# HC32F558 register map
File version: 1.0
CPU: CM4 r0p1, little endian, MPU, FPU, 4 interrupt priority bits
Registers are 32-bit, read-write, reset 0x0 unless marked. A register's access mark holds for its fields unless they carry their own. Offsets are from the block's base; [hi:lo] are bit positions; {n}, {i} and the like mark numbered series; 'fields as' and 'values as' point back to an identical list.

## HRPWM1 — desc HRPWM
Base 0x40034000
Same registers: HRPWM2 0x40034400, HRPWM3 0x40034800, HRPWM4 0x40034C00, HRPWM5 0x40035000, HRPWM6 0x40035400, HRPWM7 0x40035800, HRPWM8 0x40035C00
0x00 CNTER
  [16:0] CNT
0x04 UPDAR
  [16:0] UPDA
0x28 PHSCMP7A reset 0x3FFC0
  [17:0] PHSCMP7A
0x2C PHSCMP7B reset 0x3FFC0
  [17:0] PHSCMP7B
0x30 PHSCMP6A reset 0x3FFC0
  [17:0] PHSCMP6A
0x34 PHSCMP6B reset 0x3FFC0
  [17:0] PHSCMP6B
0x38 PHSCMP5A reset 0x3FFC0
  [17:0] PHSCMP5A
0x3C PHSCMP5B reset 0x3FFC0
  [17:0] PHSCMP5B
0x40 PHSCMP4A reset 0x3FFC0
  [17:0] PHSCMP4A
0x44 PHSCMP4B reset 0x3FFC0
  [17:0] PHSCMP4B
0x48 PHSCMP3A reset 0x3FFC0
  [17:0] PHSCMP3A
0x4C PHSCMP3B reset 0x3FFC0
  [17:0] PHSCMP3B
0x50 PHSCMP2A reset 0x3FFC0
  [17:0] PHSCMP2A
0x54 PHSCMP2B reset 0x3FFC0
  [17:0] PHSCMP2B
0x58 PHSCMP1A reset 0x3FFC0
  [17:0] PHSCMP1A
0x5C PHSCMP1B reset 0x3FFC0
  [17:0] PHSCMP1B
0x60 HRPERAR reset 0x1FFC0
  [16:0] HRPERA
0x64 HRPERBR reset 0x1FFC0
  [16:0] HRPERB
0x68 HRGCMAR reset 0x1FFC0
  [16:0] HRGCMA
0x6C HRGCMCR reset 0x1FFC0
  [16:0] HRGCMC
0x70 HRGCMBR reset 0x1FFC0
  [16:0] HRGCMB
0x74 HRGCMDR reset 0x1FFC0
  [16:0] HRGCMD
0x78 HRGCMER reset 0x1FFC0
  [16:0] HRGCME
0x7C HRGCMGR reset 0x1FFC0
  [16:0] HRGCMG
0x80 HRGCMFR reset 0x1FFC0
  [16:0] HRGCMF
0x84 HRGCMHR reset 0x1FFC0
  [16:0] HRGCMH
0x88 SCMAR reset 0x1FFC0
  [16:0] SCMA
0x8C SCMCR reset 0x1FFC0
  [16:0] SCMC
0x90 SCMBR reset 0x1FFC0
  [16:0] SCMB
0x94 SCMDR reset 0x1FFC0
  [16:0] SCMD
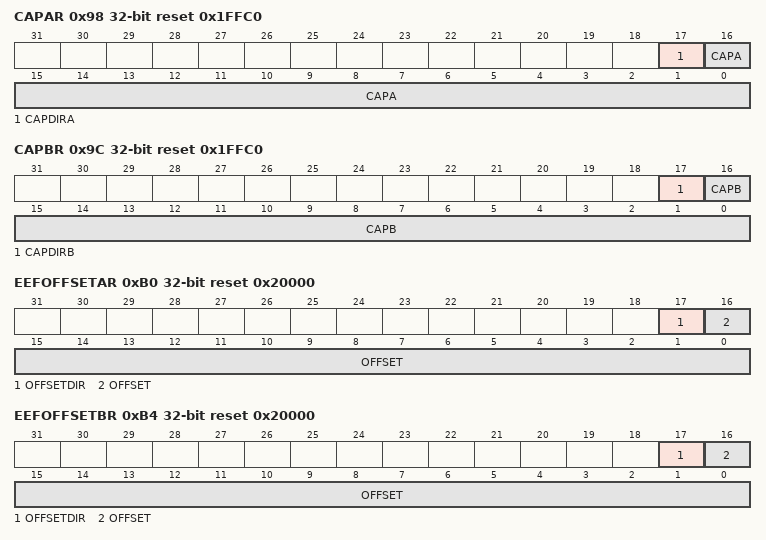
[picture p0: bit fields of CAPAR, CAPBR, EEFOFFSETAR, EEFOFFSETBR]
0x98 CAPAR reset 0x1FFC0
  [17] CAPDIRA ro, [16:0] CAPA
0x9C CAPBR reset 0x1FFC0
  [17] CAPDIRB ro, [16:0] CAPB
0xA0 HRDTUAR reset 0x1FFC0
  [16:0] HRDTUA
0xA4 HRDTUBR reset 0x1FFC0
  [16:0] HRDTUB
0xA8 HRDTDAR reset 0x1FFC0
  [16:0] HRDTDA
0xAC HRDTDBR reset 0x1FFC0
  [16:0] HRDTDB
0xB0 EEFOFFSETAR reset 0x20000
  [17] OFFSETDIR, [16:0] OFFSET
0xB4 EEFOFFSETBR reset 0x20000
  [17] OFFSETDIR, [16:0] OFFSET
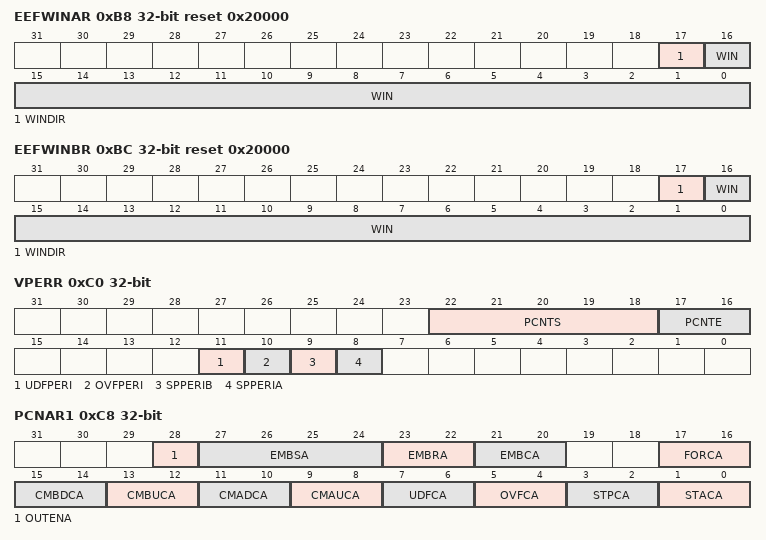
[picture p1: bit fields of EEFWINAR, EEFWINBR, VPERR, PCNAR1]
0xB8 EEFWINAR reset 0x20000
  [17] WINDIR, [16:0] WIN
0xBC EEFWINBR reset 0x20000
  [17] WINDIR, [16:0] WIN
0xC0 VPERR
  [22:18] PCNTS, [17:16] PCNTE, [11] UDFPERI, [10] OVFPERI, [9] SPPERIB, [8] SPPERIA
0xC4 BVPERR
  [22:18] PCNTS
0xC8 PCNAR1
  [28] OUTENA, [27:24] EMBSA, [23:22] EMBRA, [21:20] EMBCA, [17:16] FORCA, [15:14] CMBDCA, [13:12] CMBUCA, [11:10] CMADCA, [9:8] CMAUCA, [7:6] UDFCA, [5:4] OVFCA, [3:2] STPCA, [1:0] STACA
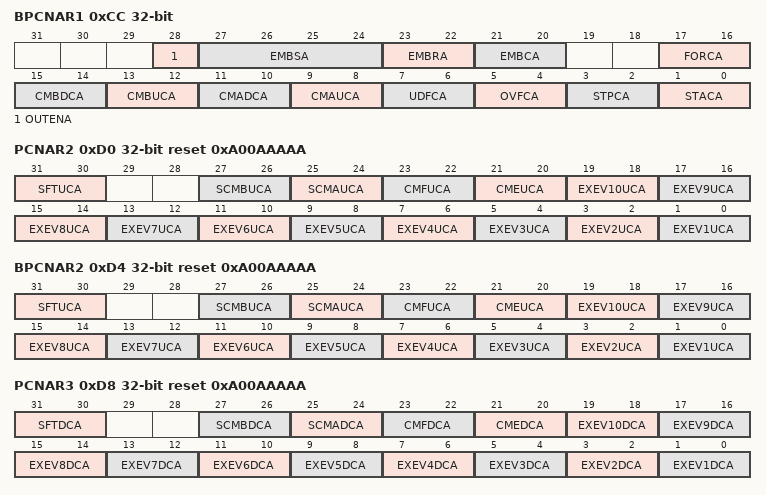
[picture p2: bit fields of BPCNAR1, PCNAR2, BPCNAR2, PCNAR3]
0xCC BPCNAR1
  fields as PCNAR1
0xD0 PCNAR2 reset 0xA00AAAAA
  [31:30] SFTUCA, [27:26] SCMBUCA, [25:24] SCMAUCA, [23:22] CMFUCA, [21:20] CMEUCA, [2n-1:2n-2] EXEV{n}UCA (n=1..10)
0xD4 BPCNAR2 reset 0xA00AAAAA
  fields as PCNAR2
0xD8 PCNAR3 reset 0xA00AAAAA
  [31:30] SFTDCA, [27:26] SCMBDCA, [25:24] SCMADCA, [23:22] CMFDCA, [21:20] CMEDCA, [2n-1:2n-2] EXEV{n}DCA (n=1..10)
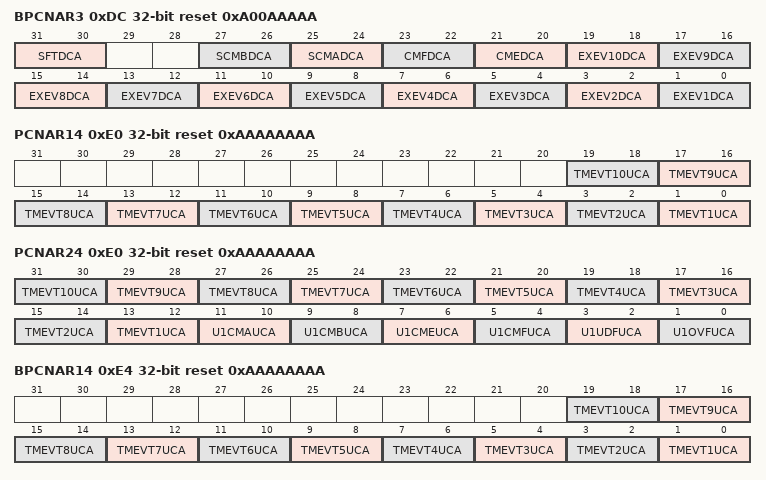
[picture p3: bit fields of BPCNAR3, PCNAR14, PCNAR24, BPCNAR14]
0xDC BPCNAR3 reset 0xA00AAAAA
  fields as PCNAR3
0xE0 PCNAR14 reset 0xAAAAAAAA
  [2n-1:2n-2] TMEVT{n}UCA (n=1..10)
0xE0 PCNAR24 reset 0xAAAAAAAA (alternate view of PCNAR14)
  [2n+11:2n+10] TMEVT{n}UCA (n=1..10), [11:10] U1CMAUCA, [9:8] U1CMBUCA, [7:6] U1CMEUCA, [5:4] U1CMFUCA, [3:2] U1UDFUCA, [1:0] U1OVFUCA
0xE4 BPCNAR14 reset 0xAAAAAAAA
  [2n-1:2n-2] TMEVT{n}UCA (n=1..10)
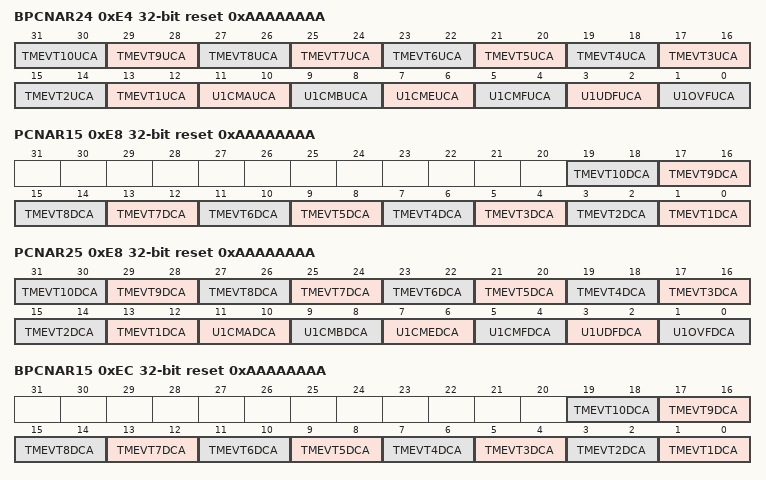
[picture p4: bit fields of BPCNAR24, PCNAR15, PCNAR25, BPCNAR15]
0xE4 BPCNAR24 reset 0xAAAAAAAA (alternate view of BPCNAR14)
  fields as PCNAR24
0xE8 PCNAR15 reset 0xAAAAAAAA
  [2n-1:2n-2] TMEVT{n}DCA (n=1..10)
0xE8 PCNAR25 reset 0xAAAAAAAA (alternate view of PCNAR15)
  [2n+11:2n+10] TMEVT{n}DCA (n=1..10), [11:10] U1CMADCA, [9:8] U1CMBDCA, [7:6] U1CMEDCA, [5:4] U1CMFDCA, [3:2] U1UDFDCA, [1:0] U1OVFDCA
0xEC BPCNAR15 reset 0xAAAAAAAA
  [2n-1:2n-2] TMEVT{n}DCA (n=1..10)
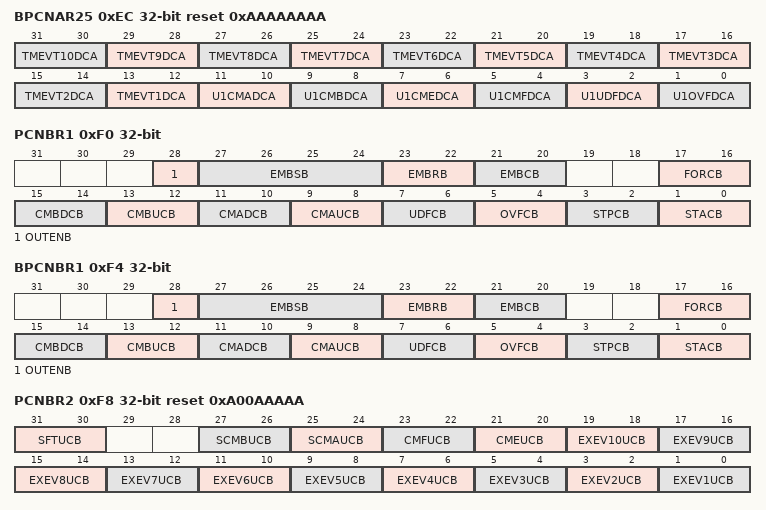
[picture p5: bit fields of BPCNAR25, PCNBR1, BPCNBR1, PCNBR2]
0xEC BPCNAR25 reset 0xAAAAAAAA (alternate view of BPCNAR15)
  fields as PCNAR25
0xF0 PCNBR1
  [28] OUTENB, [27:24] EMBSB, [23:22] EMBRB, [21:20] EMBCB, [17:16] FORCB, [15:14] CMBDCB, [13:12] CMBUCB, [11:10] CMADCB, [9:8] CMAUCB, [7:6] UDFCB, [5:4] OVFCB, [3:2] STPCB, [1:0] STACB
0xF4 BPCNBR1
  fields as PCNBR1
0xF8 PCNBR2 reset 0xA00AAAAA
  [31:30] SFTUCB, [27:26] SCMBUCB, [25:24] SCMAUCB, [23:22] CMFUCB, [21:20] CMEUCB, [2n-1:2n-2] EXEV{n}UCB (n=1..10)
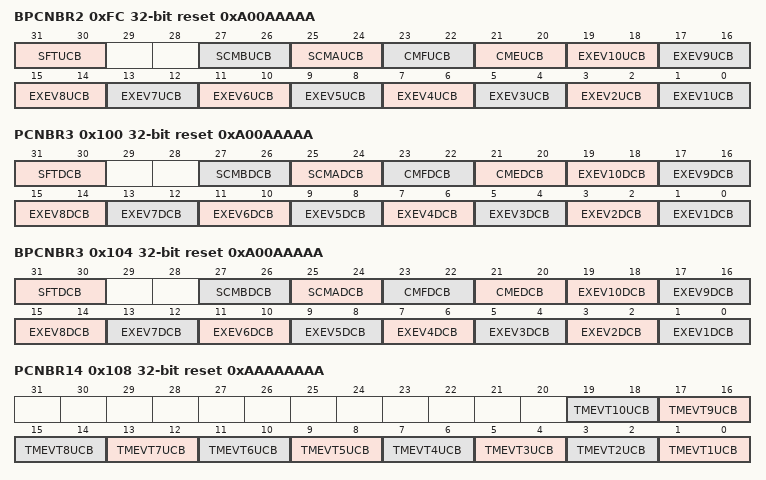
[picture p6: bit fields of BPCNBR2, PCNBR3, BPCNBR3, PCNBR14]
0xFC BPCNBR2 reset 0xA00AAAAA
  fields as PCNBR2
0x100 PCNBR3 reset 0xA00AAAAA
  [31:30] SFTDCB, [27:26] SCMBDCB, [25:24] SCMADCB, [23:22] CMFDCB, [21:20] CMEDCB, [2n-1:2n-2] EXEV{n}DCB (n=1..10)
0x104 BPCNBR3 reset 0xA00AAAAA
  fields as PCNBR3
0x108 PCNBR14 reset 0xAAAAAAAA
  [2n-1:2n-2] TMEVT{n}UCB (n=1..10)
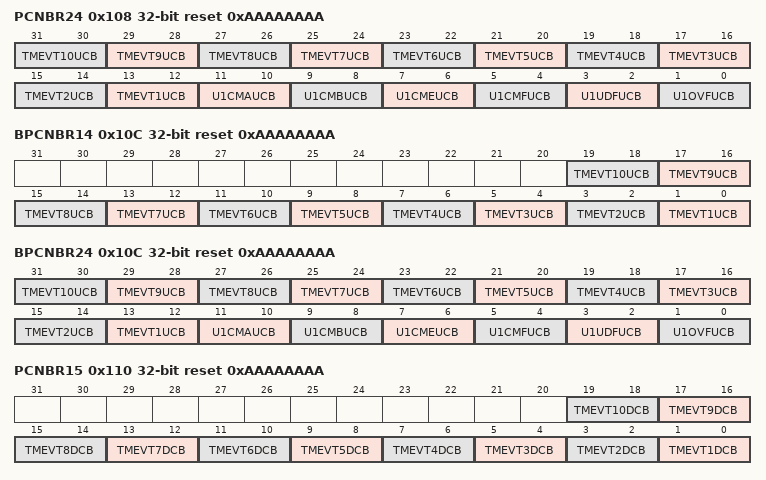
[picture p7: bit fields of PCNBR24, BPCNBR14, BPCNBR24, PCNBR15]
0x108 PCNBR24 reset 0xAAAAAAAA (alternate view of PCNBR14)
  [2n+11:2n+10] TMEVT{n}UCB (n=1..10), [11:10] U1CMAUCB, [9:8] U1CMBUCB, [7:6] U1CMEUCB, [5:4] U1CMFUCB, [3:2] U1UDFUCB, [1:0] U1OVFUCB
0x10C BPCNBR14 reset 0xAAAAAAAA
  [2n-1:2n-2] TMEVT{n}UCB (n=1..10)
0x10C BPCNBR24 reset 0xAAAAAAAA (alternate view of BPCNBR14)
  fields as PCNBR24
0x110 PCNBR15 reset 0xAAAAAAAA
  [2n-1:2n-2] TMEVT{n}DCB (n=1..10)
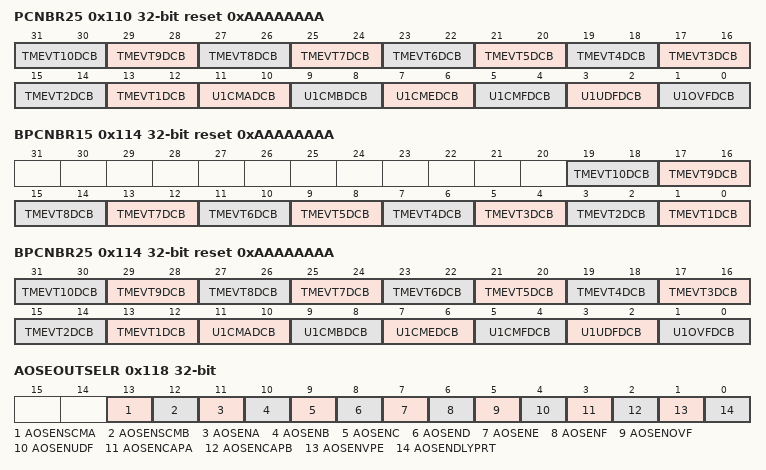
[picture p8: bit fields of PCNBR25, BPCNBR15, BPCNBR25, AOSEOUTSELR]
0x110 PCNBR25 reset 0xAAAAAAAA (alternate view of PCNBR15)
  [2n+11:2n+10] TMEVT{n}DCB (n=1..10), [11:10] U1CMADCB, [9:8] U1CMBDCB, [7:6] U1CMEDCB, [5:4] U1CMFDCB, [3:2] U1UDFDCB, [1:0] U1OVFDCB
0x114 BPCNBR15 reset 0xAAAAAAAA
  [2n-1:2n-2] TMEVT{n}DCB (n=1..10)
0x114 BPCNBR25 reset 0xAAAAAAAA (alternate view of BPCNBR15)
  fields as PCNBR25
0x118 AOSEOUTSELR
  [13] AOSENSCMA, [12] AOSENSCMB, [11] AOSENA, [10] AOSENB, [9] AOSENC, [8] AOSEND, [7] AOSENE, [6] AOSENF, [5] AOSENOVF, [4] AOSENUDF, [3] AOSENCAPA, [2] AOSENCAPB, [1] AOSENVPE, [0] AOSENDLYPRT
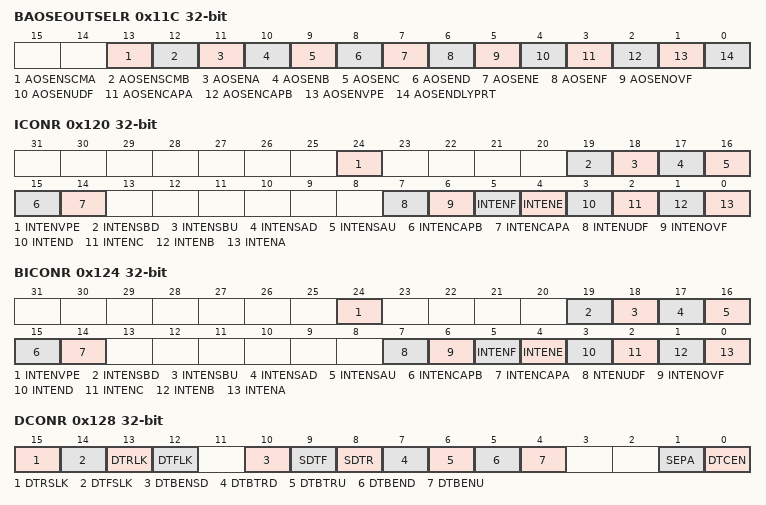
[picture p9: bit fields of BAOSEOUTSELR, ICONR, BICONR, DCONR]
0x11C BAOSEOUTSELR
  fields as AOSEOUTSELR
0x120 ICONR
  [24] INTENVPE, [19] INTENSBD, [18] INTENSBU, [17] INTENSAD, [16] INTENSAU, [15] INTENCAPB, [14] INTENCAPA, [7] INTENUDF, [6] INTENOVF, [5] INTENF, [4] INTENE, [3] INTEND, [2] INTENC, [1] INTENB, [0] INTENA
0x124 BICONR
  [24] INTENVPE, [19] INTENSBD, [18] INTENSBU, [17] INTENSAD, [16] INTENSAU, [15] INTENCAPB, [14] INTENCAPA, [7] NTENUDF, [6] INTENOVF, [5] INTENF, [4] INTENE, [3] INTEND, [2] INTENC, [1] INTENB, [0] INTENA
0x128 DCONR
  [15] DTRSLK, [14] DTFSLK, [13] DTRLK, [12] DTFLK, [10] DTBENSD, [9] SDTF, [8] SDTR, [7] DTBTRD, [6] DTBTRU, [5] DTBEND, [4] DTBENU, [1] SEPA, [0] DTCEN
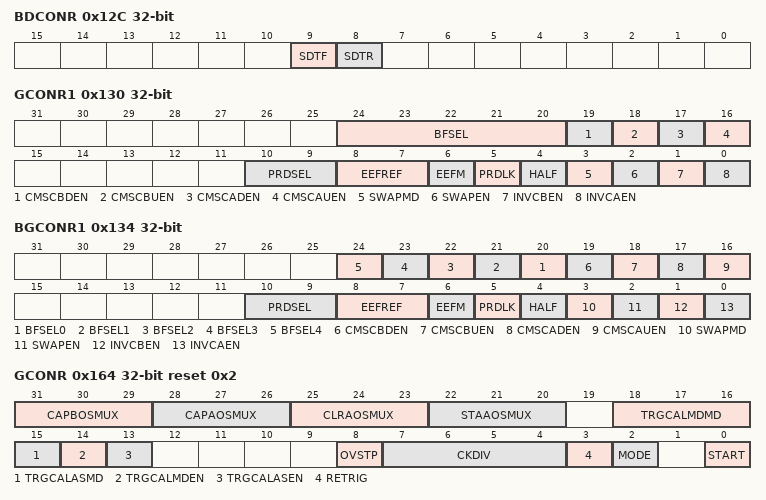
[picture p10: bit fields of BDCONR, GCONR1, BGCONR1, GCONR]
0x12C BDCONR
  [9] SDTF, [8] SDTR
0x130 GCONR1
  [24:20] BFSEL, [19] CMSCBDEN, [18] CMSCBUEN, [17] CMSCADEN, [16] CMSCAUEN, [10:9] PRDSEL, [8:7] EEFREF, [6] EEFM, [5] PRDLK, [4] HALF, [3] SWAPMD, [2] SWAPEN, [1] INVCBEN, [0] INVCAEN
0x134 BGCONR1
  [n+20] BFSEL{n} (n=0..4), [19] CMSCBDEN, [18] CMSCBUEN, [17] CMSCADEN, [16] CMSCAUEN, [10:9] PRDSEL, [8:7] EEFREF, [6] EEFM, [5] PRDLK, [4] HALF, [3] SWAPMD, [2] SWAPEN, [1] INVCBEN, [0] INVCAEN
0x164 GCONR reset 0x2
  [31:29] CAPBOSMUX, [28:26] CAPAOSMUX, [25:23] CLRAOSMUX, [22:20] STAAOSMUX, [18:16] TRGCALMDMD, [15] TRGCALASMD, [14] TRGCALMDEN, [13] TRGCALASEN, [8] OVSTP, [7:4] CKDIV, [3] RETRIG, [2] MODE, [0] START
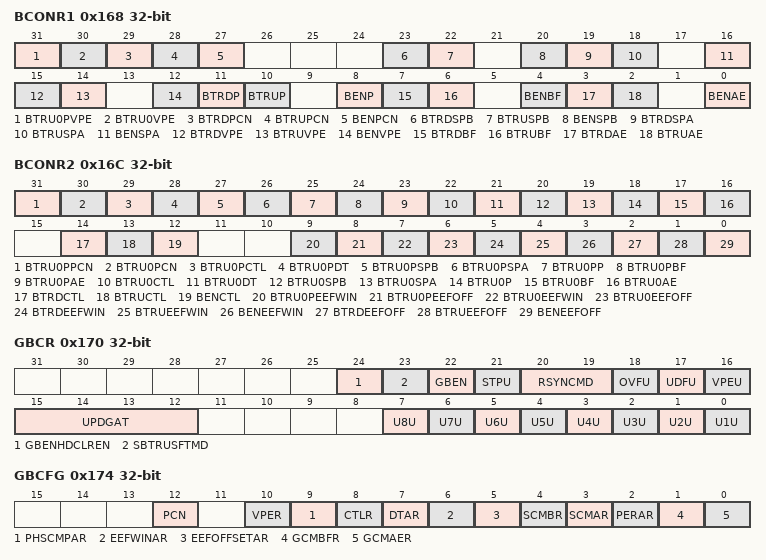
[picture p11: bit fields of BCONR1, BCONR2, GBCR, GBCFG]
0x168 BCONR1
  [31] BTRU0PVPE, [30] BTRU0VPE, [29] BTRDPCN, [28] BTRUPCN, [27] BENPCN, [23] BTRDSPB, [22] BTRUSPB, [20] BENSPB, [19] BTRDSPA, [18] BTRUSPA, [16] BENSPA, [15] BTRDVPE, [14] BTRUVPE, [12] BENVPE, [11] BTRDP, [10] BTRUP, [8] BENP, [7] BTRDBF, [6] BTRUBF, [4] BENBF, [3] BTRDAE, [2] BTRUAE, [0] BENAE
0x16C BCONR2
  [31] BTRU0PPCN, [30] BTRU0PCN, [29] BTRU0PCTL, [28] BTRU0PDT, [27] BTRU0PSPB, [26] BTRU0PSPA, [25] BTRU0PP, [24] BTRU0PBF, [23] BTRU0PAE, [22] BTRU0CTL, [21] BTRU0DT, [20] BTRU0SPB, [19] BTRU0SPA, [18] BTRU0P, [17] BTRU0BF, [16] BTRU0AE, [14] BTRDCTL, [13] BTRUCTL, [12] BENCTL, [9] BTRU0PEEFWIN, [8] BTRU0PEEFOFF, [7] BTRU0EEFWIN, [6] BTRU0EEFOFF, [5] BTRDEEFWIN, [4] BTRUEEFWIN, [3] BENEEFWIN, [2] BTRDEEFOFF, [1] BTRUEEFOFF, [0] BENEEFOFF
0x170 GBCR
  [24] GBENHDCLREN, [23] SBTRUSFTMD, [22] GBEN, [21] STPU, [20:19] RSYNCMD, [18] OVFU, [17] UDFU, [16] VPEU, [15:12] UPDGAT, [n-1] U{n}U (n=1..8)
0x174 GBCFG
  [12] PCN, [10] VPER, [9] PHSCMPAR, [8] CTLR, [7] DTAR, [6] EEFWINAR, [5] EEFOFFSETAR, [4] SCMBR, [3] SCMAR, [2] PERAR, [1] GCMBFR, [0] GCMAER
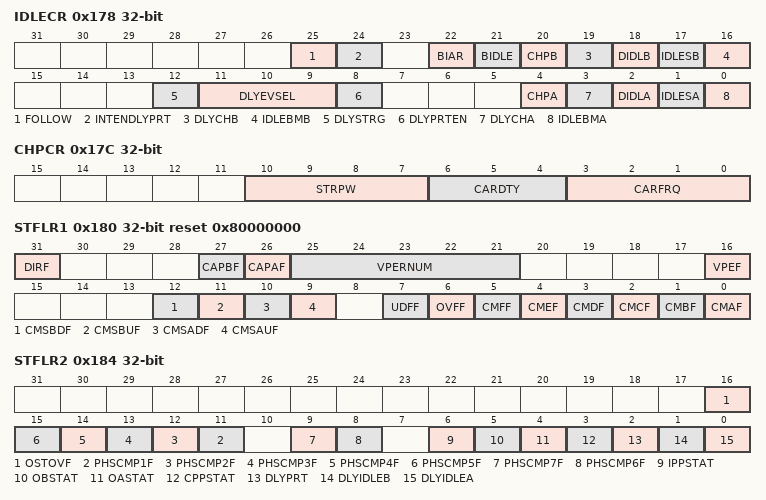
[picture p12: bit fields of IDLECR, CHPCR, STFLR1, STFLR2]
0x178 IDLECR
  [25] FOLLOW, [24] INTENDLYPRT, [22] BIAR, [21] BIDLE, [20] CHPB, [19] DLYCHB, [18] DIDLB, [17] IDLESB, [16] IDLEBMB, [12] DLYSTRG, [11:9] DLYEVSEL, [8] DLYPRTEN, [4] CHPA, [3] DLYCHA, [2] DIDLA, [1] IDLESA, [0] IDLEBMA
0x17C CHPCR
  [10:7] STRPW, [6:4] CARDTY, [3:0] CARFRQ
0x180 STFLR1 reset 0x80000000
  [31] DIRF ro, [27] CAPBF, [26] CAPAF, [25:21] VPERNUM ro, [16] VPEF, [12] CMSBDF, [11] CMSBUF, [10] CMSADF, [9] CMSAUF, [7] UDFF, [6] OVFF, [5] CMFF, [4] CMEF, [3] CMDF, [2] CMCF, [1] CMBF, [0] CMAF
0x184 STFLR2
  [16] OSTOVF, [n+10] PHSCMP{n}F (n=1..5), [9] PHSCMP7F, [8] PHSCMP6F, [6] IPPSTAT, [5] OBSTAT, [4] OASTAT, [3] CPPSTAT, [2] DLYPRT, [1] DLYIDLEB, [0] DLYIDLEA
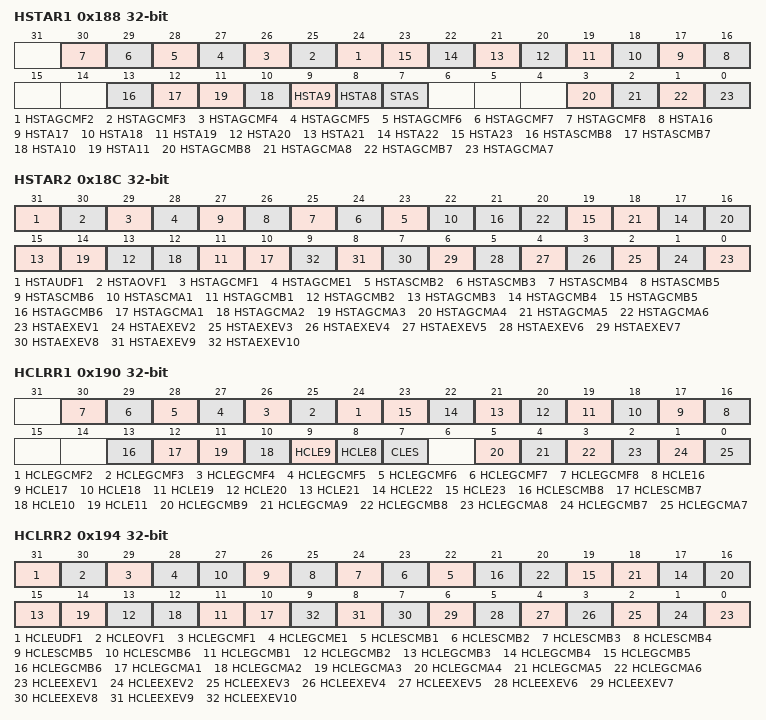
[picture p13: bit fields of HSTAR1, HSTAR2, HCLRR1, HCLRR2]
0x188 HSTAR1
  [n+22] HSTAGCMF{n} (n=2..8), [n] HSTA{n} (n=16..23), [13] HSTASCMB8, [12] HSTASCMB7, [n] HSTA{n} (n=8..11), [7] STAS, [3] HSTAGCMB8, [2] HSTAGCMA8, [1] HSTAGCMB7, [0] HSTAGCMA7
0x18C HSTAR2
  [31] HSTAUDF1, [30] HSTAOVF1, [29] HSTAGCMF1, [28] HSTAGCME1, [n+21] HSTASCMB{n} (n=2..6), [22] HSTASCMA1, [2n+9] HSTAGCMB{n} (n=1..6), [2n+8] HSTAGCMA{n} (n=1..6), [n-1] HSTAEXEV{n} (n=1..10)
0x190 HCLRR1
  [n+22] HCLEGCMF{n} (n=2..8), [n] HCLE{n} (n=16..23), [13] HCLESCMB8, [12] HCLESCMB7, [n] HCLE{n} (n=8..11), [7] CLES, [5] HCLEGCMB9, [4] HCLEGCMA9, [3] HCLEGCMB8, [2] HCLEGCMA8, [1] HCLEGCMB7, [0] HCLEGCMA7
0x194 HCLRR2
  [31] HCLEUDF1, [30] HCLEOVF1, [29] HCLEGCMF1, [28] HCLEGCME1, [n+21] HCLESCMB{n} (n=1..6), [2n+9] HCLEGCMB{n} (n=1..6), [2n+8] HCLEGCMA{n} (n=1..6), [n-1] HCLEEXEV{n} (n=1..10)
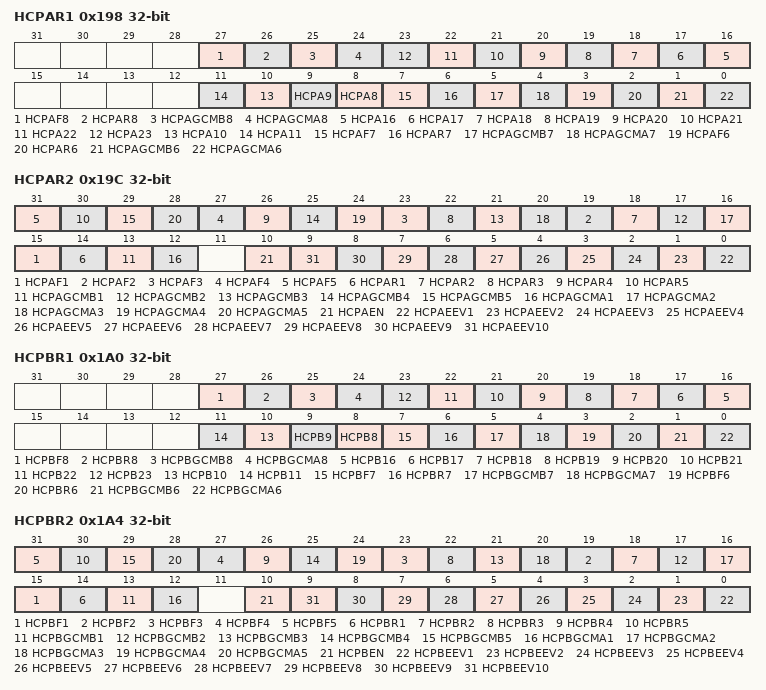
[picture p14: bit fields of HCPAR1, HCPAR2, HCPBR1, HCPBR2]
0x198 HCPAR1
  [27] HCPAF8, [26] HCPAR8, [25] HCPAGCMB8, [24] HCPAGCMA8, [n] HCPA{n} (n=16..23), [n] HCPA{n} (n=8..11), [7] HCPAF7, [6] HCPAR7, [5] HCPAGCMB7, [4] HCPAGCMA7, [3] HCPAF6, [2] HCPAR6, [1] HCPAGCMB6, [0] HCPAGCMA6
0x19C HCPAR2
  [4n+11] HCPAF{n} (n=1..5), [4n+10] HCPAR{n} (n=1..5), [4n+9] HCPAGCMB{n} (n=1..5), [4n+8] HCPAGCMA{n} (n=1..5), [10] HCPAEN, [n-1] HCPAEEV{n} (n=1..10)
0x1A0 HCPBR1
  [27] HCPBF8, [26] HCPBR8, [25] HCPBGCMB8, [24] HCPBGCMA8, [n] HCPB{n} (n=16..23), [n] HCPB{n} (n=8..11), [7] HCPBF7, [6] HCPBR7, [5] HCPBGCMB7, [4] HCPBGCMA7, [3] HCPBF6, [2] HCPBR6, [1] HCPBGCMB6, [0] HCPBGCMA6
0x1A4 HCPBR2
  [4n+11] HCPBF{n} (n=1..5), [4n+10] HCPBR{n} (n=1..5), [4n+9] HCPBGCMB{n} (n=1..5), [4n+8] HCPBGCMA{n} (n=1..5), [10] HCPBEN, [n-1] HCPBEEV{n} (n=1..10)
0x1A8 EEFLTCR1
  [30] EEINTPOL, [6n-1] EE{n}TMO (n=1..5), [6n-2:6n-5] EE{n}FM (n=1..5), [6n-6] EE{n}LAT (n=1..5)
0x1AC EEFLTCR2
  [6n-31] EE{n}TMO (n=6..10), [6n-32:6n-35] EE{n}FM (n=6..10), [6n-36] EE{n}LAT (n=6..10)
0x1B0 EEFLTCR3
  [13:8] EEVACNT, [7:4] EEVASEL, [2] EEVARSTM, [1] EEVACRES wo, [0] EEVACE
0x1B4 LINKCR1
  [31:28] OFFWINLINK, [27:24] SCMBLINK, [23:20] SCMALINK, [19:16] GCMFLINK, [15:12] GCMELINK, [11:8] GCMBLINK, [7:4] GCMALINK, [3:0] PRDLINK
0x1B8 CR
  [29:28] DELGCME, [27:26] DELGCMA, [25] GTGCMB, [24] GTGCMF, [23] TRGHLF, [22] PSHPLL, [21:20] INTLVD, [19] RAMPSS, [18:17] RAMPRS, [16] RAMPEN, [14:12] DACSRC, [9:8] DACSYNC2, [5:4] DACSYNC1, [3] EN
0x1BC PHSCTL
  [15:12] MINTLVD, [10] BTRDPHS, [9] BTRUPHS, [8] BENPHS, [7] PHSFORCB, [6] PHSFORCA, [3:1] PHCMPSEL, [0] PHSEN
0x1C0 LINKCR2
  [7:4] DTDLINK, [3:0] DTULINK
0x1C4 TRGCALDATR
  [16:0] TRGCALDAT
0x1C8 UDIRCFG
  [n-1] EEV{n} (n=1..10)
0x1CC DDIRCFG
  [n-1] EEV{n} (n=1..10)
0x1D0 TRIPOUTSEL
  [n+8] EEV{n} (n=1..5), [n] EMBEVT{n} (n=0..7)
0x1D4 DECTL
  [15:8] REENTRYDLY, [1] MODE, [0] ENABLE
0x1D8 DECOMPSEL
  [13:8] TRIPH, [5:0] TRIPL
0x1DC DEACTCTL
  [16] TRIPENABLE, [6] TRIPSELB, [5:4] PWMB, [2] TRIPSELA, [1:0] PWMA
0x1E0 DESTAT
  [0] DEACTIVE
0x1E4 DEFRC
  [0] DEACTIVE
0x1E8 DECLR
  [0] DEACTIVE
0x1EC DEMONCNT
  [15:0] CNT
0x1F0 DEMONCTL
  [0] ENABLE
0x1F4 DEMONSTEP
  [23:16] DECSTEP, [7:0] INCSTEP
0x1F8 DEMONRHRES
  [15:0] THRESHOLD
0x1FC MINDBCFG
  [28] POLSELB, [23:20] SELB, [19] SELBLOCKB, [18] INVERTB, [16] ENABLEB, [12] POLSELA, [7:4] SELA, [3] SELBLOCKA, [2] INVERTA, [0] ENABLEA
0x200 MINDBDLY
  [31:16] DELAYB, [15:0] DELAYA
0x204 LUTCTLA reset 0x1
  [23:16] LUTDEC, [7:4] SELXBAR, [0] BYPASS
0x208 LUTCTLB reset 0x1
  [23:16] LUTDEC, [7:4] SELXBAR, [0] BYPASS
